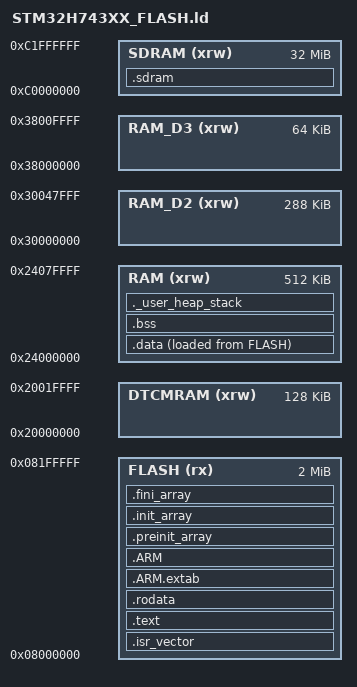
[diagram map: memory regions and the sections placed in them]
/*
******************************************************************************
**
**  File        : LinkerScript.ld
**
**  Author      : STM32CubeMX
**
**  Abstract    : Linker script for STM32H743IITx series
**                2048Kbytes FLASH and 1056Kbytes RAM
**
******************************************************************************
*/

/* Entry Point */
ENTRY(Reset_Handler)

/* Highest address of the user mode stack */
_estack = ORIGIN(RAM) + LENGTH(RAM);
_sstack = _estack - _Min_Stack_Size;

/* Generate a link error if heap and stack don't fit into RAM */
_Min_Heap_Size = 0x200;
_Min_Stack_Size = 0x400;

/* Specify the memory areas */
MEMORY
{
FLASH (rx)         : ORIGIN = 0x08000000, LENGTH = 2048K
DTCMRAM (xrw)      : ORIGIN = 0x20000000, LENGTH = 128K
RAM (xrw)          : ORIGIN = 0x24000000, LENGTH = 512K
RAM_D2 (xrw)       : ORIGIN = 0x30000000, LENGTH = 288K
RAM_D3 (xrw)       : ORIGIN = 0x38000000, LENGTH = 64K
SDRAM (xrw)        : ORIGIN = 0xC0000000, LENGTH = 32M
}

/* Define output sections */
SECTIONS
{
  /* The startup code goes first into FLASH */
  .isr_vector :
  {
    . = ALIGN(4);
    KEEP(*(.isr_vector))
    . = ALIGN(4);
  } >FLASH

  /* The program code and other data goes into FLASH */
  .text :
  {
    . = ALIGN(4);
    *(.text)
    *(.text*)
    *(.glue_7)
    *(.glue_7t)
    *(.eh_frame)
    KEEP (*(.init))
    KEEP (*(.fini))
    . = ALIGN(4);
    _etext = .;
  } >FLASH

  /* Constant data goes into FLASH */
  .rodata :
  {
    . = ALIGN(4);
    *(.rodata)
    *(.rodata*)
    . = ALIGN(4);
  } >FLASH

  .ARM.extab (READONLY) :
  {
    . = ALIGN(4);
    *(.ARM.extab* .gnu.linkonce.armextab.*)
    . = ALIGN(4);
  } >FLASH

  .ARM (READONLY) :
  {
    . = ALIGN(4);
    __exidx_start = .;
    *(.ARM.exidx*)
    __exidx_end = .;
    . = ALIGN(4);
  } >FLASH

  .preinit_array (READONLY) :
  {
    . = ALIGN(4);
    PROVIDE_HIDDEN (__preinit_array_start = .);
    KEEP (*(.preinit_array*))
    PROVIDE_HIDDEN (__preinit_array_end = .);
    . = ALIGN(4);
  } >FLASH

  .init_array (READONLY) :
  {
    . = ALIGN(4);
    PROVIDE_HIDDEN (__init_array_start = .);
    KEEP (*(SORT(.init_array.*)))
    KEEP (*(.init_array*))
    PROVIDE_HIDDEN (__init_array_end = .);
    . = ALIGN(4);
  } >FLASH

  .fini_array (READONLY) :
  {
    . = ALIGN(4);
    PROVIDE_HIDDEN (__fini_array_start = .);
    KEEP (*(SORT(.fini_array.*)))
    KEEP (*(.fini_array*))
    PROVIDE_HIDDEN (__fini_array_end = .);
    . = ALIGN(4);
  } >FLASH

  /* used by the startup to initialize data */
  _sidata = LOADADDR(.data);

  /* Initialized data sections */
  .data :
  {
    . = ALIGN(4);
    _sdata = .;
    *(.data)
    *(.data*)
    *(.RamFunc)
    *(.RamFunc*)
    . = ALIGN(4);
    _edata = .;
  } >RAM AT> FLASH

  /* Uninitialized data section */
  . = ALIGN(4);
  .bss :
  {
    _sbss = .;
    __bss_start__ = _sbss;
    *(.bss)
    *(.bss*)
    *(COMMON)
    . = ALIGN(4);
    _ebss = .;
    __bss_end__ = _ebss;
  } >RAM

  /* Heap and stack */
  ._user_heap_stack :
  {
    . = ALIGN(8);
    PROVIDE ( end = . );
    PROVIDE ( _end = . );
    . = . + _Min_Heap_Size;
    . = . + _Min_Stack_Size;
    . = ALIGN(8);
  } >RAM

  /* SDRAM framebuffer section */
 .sdram (NOLOAD) :
  {
    . = ALIGN(4);
    *(.bss.ARM.__at_0XC0000000)
    *(.sdram_bss)
    . = ALIGN(4);
  } >SDRAM

  /* Remove information from standard libraries */
  /DISCARD/ :
  {
    libc.a ( * )
    libm.a ( * )
    libgcc.a ( * )
  }
}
